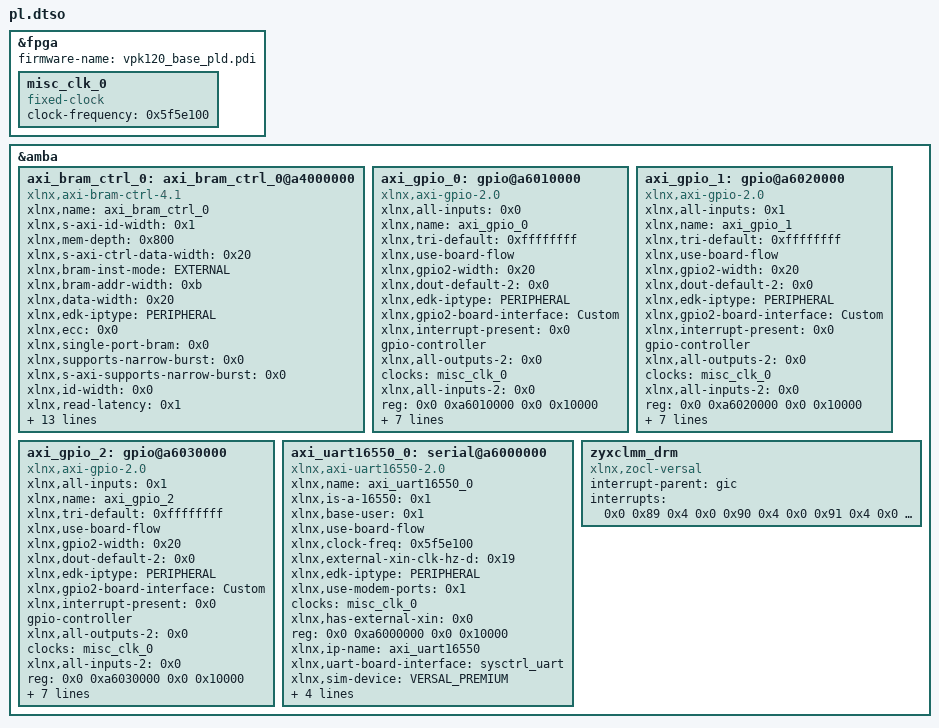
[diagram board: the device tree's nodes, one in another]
/dts-v1/;
/plugin/;

&fpga {
        firmware-name = "vpk120_base_pld.pdi";

        misc_clk_0: misc_clk_0 {
                #clock-cells = <0x0>;
                clock-frequency = <0x5f5e100>;
                compatible = "fixed-clock";
        };
};

&amba {

        axi_bram_ctrl_0: axi_bram_ctrl_0@a4000000 {
                xlnx,name = "axi_bram_ctrl_0";
                xlnx,s-axi-id-width = <0x1>;
                xlnx,mem-depth = <0x800>;
                xlnx,s-axi-ctrl-data-width = <0x20>;
                xlnx,bram-inst-mode = "EXTERNAL";
                xlnx,bram-addr-width = <0xb>;
                xlnx,data-width = <0x20>;
                clock-names = "s_axi_aclk";
                xlnx,edk-iptype = "PERIPHERAL";
                xlnx,ecc = <0x0>;
                xlnx,single-port-bram = <0x0>;
                xlnx,supports-narrow-burst = <0x0>;
                xlnx,s-axi-supports-narrow-burst = <0x0>;
                xlnx,id-width = <0x0>;
                xlnx,read-latency = <0x1>;
                xlnx,s-axi-ctrl-addr-width = <0x20>;
                clocks = <&misc_clk_0>;
                xlnx,bmg-instance = "EXTERNAL";
                reg = <0x0 0xa4000000 0x0 0x2000>;
                xlnx,ip-name = "axi_bram_ctrl";
                xlnx,fault-inject = <0x0>;
                xlnx,use-ecc = <0x0>;
                xlnx,memory-depth = <0x800>;
                xlnx,rd-cmd-optimization = <0x0>;
                xlnx,ecc-type = <0x0>;
                xlnx,ecc-onoff-reset-value = <0x0>;
                compatible = "xlnx,axi-bram-ctrl-4.1", "xlnx,axi-bram-ctrl";
                xlnx,edk-special = "BRAM_CTRL";
                xlnx,protocol = "AXI4";
        };

        axi_gpio_0: gpio@a6010000 {
                xlnx,all-inputs = <0x0>;
                xlnx,name = "axi_gpio_0";
                xlnx,tri-default = <0xffffffff>;
                xlnx,use-board-flow;
                clock-names = "s_axi_aclk";
                xlnx,gpio2-width = <0x20>;
                xlnx,dout-default-2 = <0x0>;
                xlnx,edk-iptype = "PERIPHERAL";
                xlnx,gpio2-board-interface = "Custom";
                xlnx,interrupt-present = <0x0>;
                device_type = "gpio";
                gpio-controller;
                xlnx,all-outputs-2 = <0x0>;
                clocks = <&misc_clk_0>;
                xlnx,all-inputs-2 = <0x0>;
                reg = <0x0 0xa6010000 0x0 0x10000>;
                xlnx,tri-default-2 = <0xffffffff>;
                xlnx,ip-name = "axi_gpio";
                xlnx,is-dual = <0x0>;
                xlnx,dout-default = <0x0>;
                xlnx,gpio-width = <0x4>;
                #gpio-cells = <0x2>;
                xlnx,all-outputs = <0x1>;
                compatible = "xlnx,axi-gpio-2.0", "xlnx,xps-gpio-1.00.a";
                xlnx,gpio-board-interface = "gpio_led";
        };

        axi_gpio_1: gpio@a6020000 {
                xlnx,all-inputs = <0x1>;
                xlnx,name = "axi_gpio_1";
                xlnx,tri-default = <0xffffffff>;
                xlnx,use-board-flow;
                clock-names = "s_axi_aclk";
                xlnx,gpio2-width = <0x20>;
                xlnx,dout-default-2 = <0x0>;
                xlnx,edk-iptype = "PERIPHERAL";
                xlnx,gpio2-board-interface = "Custom";
                xlnx,interrupt-present = <0x0>;
                device_type = "gpio";
                gpio-controller;
                xlnx,all-outputs-2 = <0x0>;
                clocks = <&misc_clk_0>;
                xlnx,all-inputs-2 = <0x0>;
                reg = <0x0 0xa6020000 0x0 0x10000>;
                xlnx,tri-default-2 = <0xffffffff>;
                xlnx,ip-name = "axi_gpio";
                xlnx,is-dual = <0x0>;
                xlnx,dout-default = <0x0>;
                xlnx,gpio-width = <0x2>;
                #gpio-cells = <0x2>;
                xlnx,all-outputs = <0x0>;
                compatible = "xlnx,axi-gpio-2.0", "xlnx,xps-gpio-1.00.a";
                xlnx,gpio-board-interface = "gpio_pb";
        };

        axi_gpio_2: gpio@a6030000 {
                xlnx,all-inputs = <0x1>;
                xlnx,name = "axi_gpio_2";
                xlnx,tri-default = <0xffffffff>;
                xlnx,use-board-flow;
                clock-names = "s_axi_aclk";
                xlnx,gpio2-width = <0x20>;
                xlnx,dout-default-2 = <0x0>;
                xlnx,edk-iptype = "PERIPHERAL";
                xlnx,gpio2-board-interface = "Custom";
                xlnx,interrupt-present = <0x0>;
                device_type = "gpio";
                gpio-controller;
                xlnx,all-outputs-2 = <0x0>;
                clocks = <&misc_clk_0>;
                xlnx,all-inputs-2 = <0x0>;
                reg = <0x0 0xa6030000 0x0 0x10000>;
                xlnx,tri-default-2 = <0xffffffff>;
                xlnx,ip-name = "axi_gpio";
                xlnx,is-dual = <0x0>;
                xlnx,dout-default = <0x0>;
                xlnx,gpio-width = <0x4>;
                #gpio-cells = <0x2>;
                xlnx,all-outputs = <0x0>;
                compatible = "xlnx,axi-gpio-2.0", "xlnx,xps-gpio-1.00.a";
                xlnx,gpio-board-interface = "gpio_dp";
        };

        axi_uart16550_0: serial@a6000000 {
                xlnx,name = "axi_uart16550_0";
                xlnx,is-a-16550 = <0x1>;
                xlnx,base-user = <0x1>;
                xlnx,use-board-flow;
                clock-names = "s_axi_aclk";
                xlnx,clock-freq = <0x5f5e100>;
                xlnx,external-xin-clk-hz-d = <0x19>;
                xlnx,edk-iptype = "PERIPHERAL";
                device_type = "serial";
                xlnx,use-modem-ports = <0x1>;
                clocks = <&misc_clk_0>;
                xlnx,has-external-xin = <0x0>;
                reg = <0x0 0xa6000000 0x0 0x10000>;
                xlnx,ip-name = "axi_uart16550";
                xlnx,uart-board-interface = "sysctrl_uart";
                xlnx,sim-device = "VERSAL_PREMIUM";
                xlnx,use-user-ports = <0x1>;
                xlnx,s-axi-aclk-freq-hz-d = <0x64>;
                xlnx,has-external-rclk = <0x0>;
                xlnx,external-xin-clk-hz = <0x17d7840>;
                compatible = "xlnx,axi-uart16550-2.0", "xlnx,axi-uart16550";
        };

        zyxclmm_drm {
                compatible = "xlnx,zocl-versal";
                interrupt-parent = <&gic>;
                interrupts = <0x0 0x89 0x4 0x0 0x90 0x4 0x0 0x91 0x4 0x0 0x92 0x4 0x0 0x93 0x4 0x0 0x94 0x4 0x0 0x95 0x4 0x0 0x96 0x4>;
        };
};

